# MKE15D7 register map
File version: 1.6
Registers are 32-bit, read-write, reset 0x0 unless marked. A register's access mark holds for its fields unless they carry their own. Offsets are from the block's base; [hi:lo] are bit positions; {n}, {i} and the like mark numbered series.

## FTMRA_FlashConfig — Flash configuration field
Base 0x00000400; register names take the prefix NV_
0x00 BACKKEY3 8-bit ro reset 0xFF — Backdoor Comparison Key 3.
  [7:0] KEY — Backdoor Comparison Key.
0x01 BACKKEY2 8-bit ro reset 0xFF — Backdoor Comparison Key 2.
  [7:0] KEY — Backdoor Comparison Key.
0x02 BACKKEY1 8-bit ro reset 0xFF — Backdoor Comparison Key 1.
  [7:0] KEY — Backdoor Comparison Key.
0x03 BACKKEY0 8-bit ro reset 0xFF — Backdoor Comparison Key 0.
  [7:0] KEY — Backdoor Comparison Key.
0x04 BACKKEY7 8-bit ro reset 0xFF — Backdoor Comparison Key 7.
  [7:0] KEY — Backdoor Comparison Key.
0x05 BACKKEY6 8-bit ro reset 0xFF — Backdoor Comparison Key 6.
  [7:0] KEY — Backdoor Comparison Key.
0x06 BACKKEY5 8-bit ro reset 0xFF — Backdoor Comparison Key 5.
  [7:0] KEY — Backdoor Comparison Key.
0x07 BACKKEY4 8-bit ro reset 0xFF — Backdoor Comparison Key 4.
  [7:0] KEY — Backdoor Comparison Key.
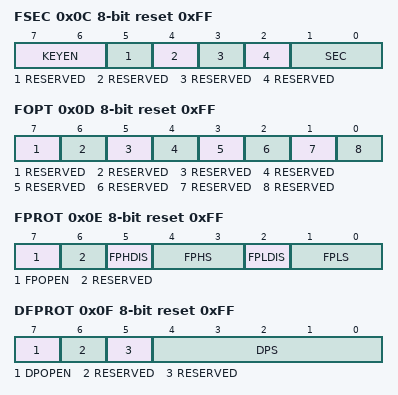
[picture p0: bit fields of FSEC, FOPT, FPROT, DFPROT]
0x0C FSEC 8-bit ro reset 0xFF — Non-volatile Flash Security Register
  [7:6] KEYEN — Backdoor Key Security Enable
  [5] RESERVED
  [4] RESERVED
  [3] RESERVED
  [2] RESERVED
  [1:0] SEC — Flash Security
0x0D FOPT 8-bit ro reset 0xFF — Non-volatile Flash Option Register
  [7] RESERVED, [6] RESERVED, [5] RESERVED, [4] RESERVED, [3] RESERVED, [2] RESERVED, [1] RESERVED, [0] RESERVED
0x0E FPROT 8-bit ro reset 0xFF — Non-volatile P-Flash Protection Register
  [7] FPOPEN, [6] RESERVED, [5] FPHDIS, [4:3] FPHS, [2] FPLDIS, [1:0] FPLS
0x0F DFPROT 8-bit ro reset 0xFF — Non-volatile D-Flash Protection Register
  [7] DPOPEN, [6] RESERVED, [5] RESERVED, [4:0] DPS

## DMAMUX — DMA channel multiplexor
Base 0x40021000; register names take the prefix DMAMUX_
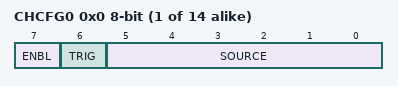
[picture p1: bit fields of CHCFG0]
{0x0+i} CHCFG{i} (i=0..13) 8-bit — Channel Configuration register
  [7] ENBL — DMA Channel Enable
    0=DMA channel is disabled. This mode is primarily used during configuration of the DMA Mux. The DMA has separate channel enables/disables, which should be used to disable or re-configure a DMA channel.; 1=DMA channel is enabled
  [6] TRIG — DMA Channel Trigger Enable
    0=Triggering is disabled. If triggering is disabled, and the ENBL bit is set, the DMA Channel will simply route the specified source to the DMA channel. (Normal mode); 1=Triggering is enabled. If triggering is enabled, and the ENBL bit is set, the DMAMUX is in Periodic Trigger mode.
  [5:0] SOURCE — DMA Channel Source (Slot)

## PIT — Periodic Interrupt Timer
Base 0x40023000; register names take the prefix PIT_
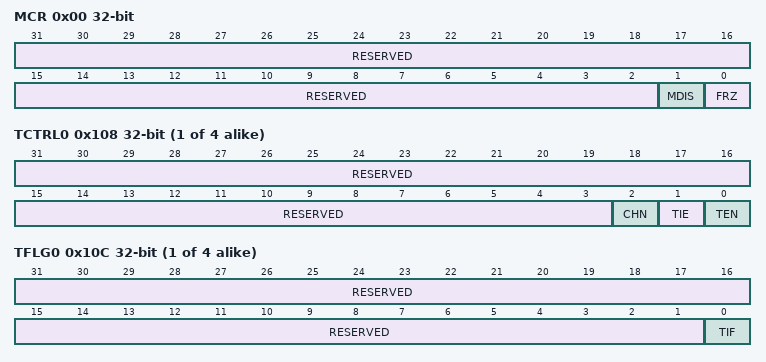
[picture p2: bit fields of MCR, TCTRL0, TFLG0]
0x00 MCR — PIT Module Control Register
  [31:2] RESERVED ro
  [1] MDIS — Module Disable
    0=Clock for PIT timers is enabled; 1=Clock for PIT timers is disabled
  [0] FRZ — Freeze
    0=Timers continue to run in Debug mode; 1=Timers are stopped in Debug mode
0xE0 LTMR64H ro — PIT Upper Lifetime Timer Register
  [31:0] LTH — Life Timer value
0xE4 LTMR64L ro — PIT Lower Lifetime Timer Register
  [31:0] LTL — Life Timer value
{0x100+0x10*i} LDVAL{i} (i=0..3) — Timer Load Value Register
  [31:0] TSV — Timer Start Value
{0x104+0x10*i} CVAL{i} (i=0..3) ro — Current Timer Value Register
  [31:0] TVL — Current Timer Value
{0x108+0x10*i} TCTRL{i} (i=0..3) — Timer Control Register
  [31:3] RESERVED ro
  [2] CHN — Chain Mode
    0=Timer is not chained; 1=Timer is chained to previous timer. For example, for Channel 2, if this field is set, Timer 2 is chained to Timer 1.
  [1] TIE — Timer Interrupt Enable
    0=Interrupt requests from Timer n are disabled; 1=Interrupt will be requested whenever TIF is set
  [0] TEN — Timer Enable
    0=Timer n is disabled; 1=Timer n is enabled
{0x10C+0x10*i} TFLG{i} (i=0..3) — Timer Flag Register
  [31:1] RESERVED ro
  [0] TIF — Timer Interrupt Flag
    0=Timeout has not yet occurred; 1=Timeout has occurred
